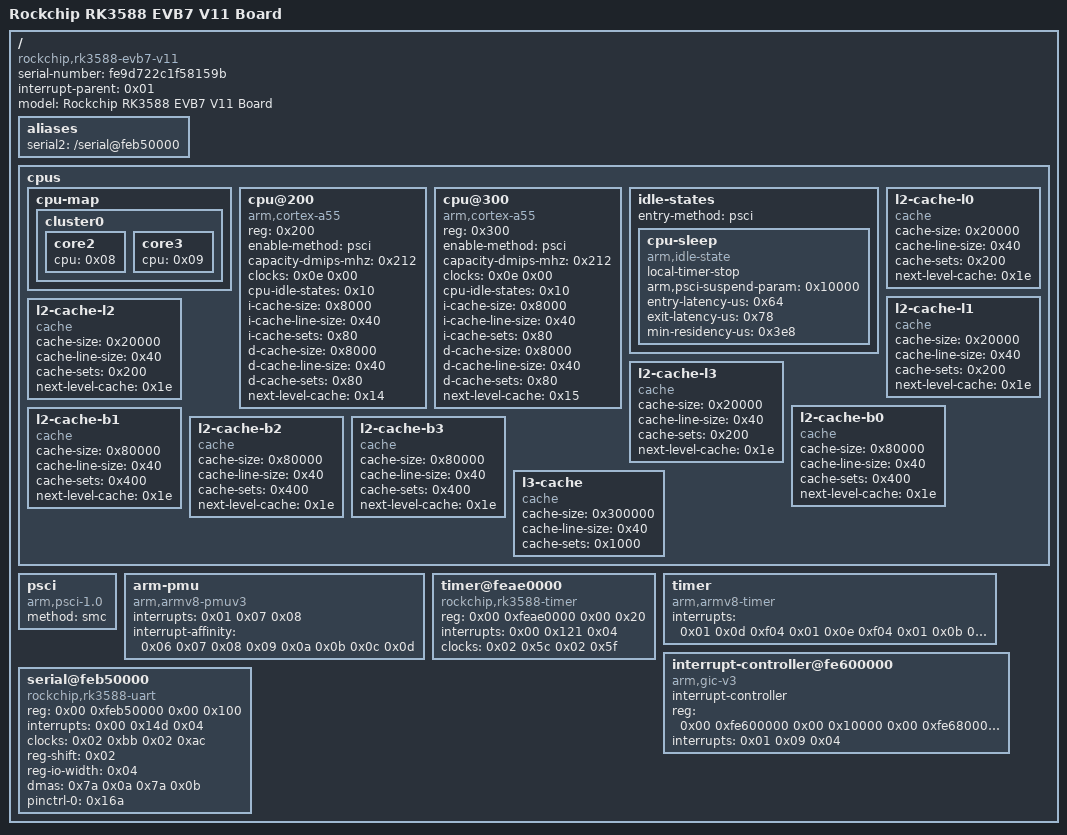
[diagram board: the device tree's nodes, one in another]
/dts-v1/;
/ {
	serial-number = "fe9d722c1f58159b";
	compatible = "rockchip,rk3588-evb7-v11\0rockchip,rk3588";
	interrupt-parent = <0x01>;
	#address-cells = <0x02>;
	#size-cells = <0x02>;
	model = "Rockchip RK3588 EVB7 V11 Board";

	aliases {
		serial2 = "/serial@feb50000";
	};

	cpus {
		#address-cells = <0x01>;
		#size-cells = <0x00>;

		cpu-map {
			cluster0 {
				core2 {
					cpu = <0x08>;
				};
				core3 {
					cpu = <0x09>;
				};
			};
		};

		cpu@200 {
			device_type = "cpu";
			compatible = "arm,cortex-a55";
			reg = <0x200>;
			enable-method = "psci";
			capacity-dmips-mhz = <0x212>;
			clocks = <0x0e 0x00>;
			cpu-idle-states = <0x10>;
			i-cache-size = <0x8000>;
			i-cache-line-size = <0x40>;
			i-cache-sets = <0x80>;
			d-cache-size = <0x8000>;
			d-cache-line-size = <0x40>;
			d-cache-sets = <0x80>;
			next-level-cache = <0x14>;
			phandle = <0x08>;
		};

		cpu@300 {
			device_type = "cpu";
			compatible = "arm,cortex-a55";
			reg = <0x300>;
			enable-method = "psci";
			capacity-dmips-mhz = <0x212>;
			clocks = <0x0e 0x00>;
			cpu-idle-states = <0x10>;
			i-cache-size = <0x8000>;
			i-cache-line-size = <0x40>;
			i-cache-sets = <0x80>;
			d-cache-size = <0x8000>;
			d-cache-line-size = <0x40>;
			d-cache-sets = <0x80>;
			next-level-cache = <0x15>;
			phandle = <0x09>;
		};

		idle-states {
			entry-method = "psci";
			cpu-sleep {
				compatible = "arm,idle-state";
				local-timer-stop;
				arm,psci-suspend-param = <0x10000>;
				entry-latency-us = <0x64>;
				exit-latency-us = <0x78>;
				min-residency-us = <0x3e8>;
				phandle = <0x10>;
			};
		};

		l2-cache-l0 {
			compatible = "cache";
			cache-size = <0x20000>;
			cache-line-size = <0x40>;
			cache-sets = <0x200>;
			next-level-cache = <0x1e>;
			phandle = <0x11>;
		};

		l2-cache-l1 {
			compatible = "cache";
			cache-size = <0x20000>;
			cache-line-size = <0x40>;
			cache-sets = <0x200>;
			next-level-cache = <0x1e>;
			phandle = <0x13>;
		};

		l2-cache-l2 {
			compatible = "cache";
			cache-size = <0x20000>;
			cache-line-size = <0x40>;
			cache-sets = <0x200>;
			next-level-cache = <0x1e>;
			phandle = <0x14>;
		};

		l2-cache-l3 {
			compatible = "cache";
			cache-size = <0x20000>;
			cache-line-size = <0x40>;
			cache-sets = <0x200>;
			next-level-cache = <0x1e>;
			phandle = <0x15>;
		};

		l2-cache-b0 {
			compatible = "cache";
			cache-size = <0x80000>;
			cache-line-size = <0x40>;
			cache-sets = <0x400>;
			next-level-cache = <0x1e>;
			phandle = <0x17>;
		};

		l2-cache-b1 {
			compatible = "cache";
			cache-size = <0x80000>;
			cache-line-size = <0x40>;
			cache-sets = <0x400>;
			next-level-cache = <0x1e>;
			phandle = <0x19>;
		};

		l2-cache-b2 {
			compatible = "cache";
			cache-size = <0x80000>;
			cache-line-size = <0x40>;
			cache-sets = <0x400>;
			next-level-cache = <0x1e>;
			phandle = <0x1b>;
		};

		l2-cache-b3 {
			compatible = "cache";
			cache-size = <0x80000>;
			cache-line-size = <0x40>;
			cache-sets = <0x400>;
			next-level-cache = <0x1e>;
			phandle = <0x1d>;
		};

		l3-cache {
			compatible = "cache";
			cache-size = <0x300000>;
			cache-line-size = <0x40>;
			cache-sets = <0x1000>;
			phandle = <0x1e>;
		};
	};

	psci {
		compatible = "arm,psci-1.0";
		method = "smc";
	};

	arm-pmu {
		compatible = "arm,armv8-pmuv3";
		interrupts = <0x01 0x07 0x08>;
		interrupt-affinity = <0x06 0x07 0x08 0x09 0x0a 0x0b 0x0c 0x0d>;
		phandle = <0x210>;
	};

	timer@feae0000 {
		compatible = "rockchip,rk3588-timer\0rockchip,rk3288-timer";
		reg = <0x00 0xfeae0000 0x00 0x20>;
		interrupts = <0x00 0x121 0x04>;
		clocks = <0x02 0x5c 0x02 0x5f>;
		clock-names = "pclk\0timer";
		phandle = <0x2b1>;
	};

	timer {
		compatible = "arm,armv8-timer";
		interrupts = <0x01 0x0d 0xf04 0x01 0x0e 0xf04 0x01 0x0b 0xf04 0x01 0x0a 0xf04>;
	};

	interrupt-controller@fe600000 {
		compatible = "arm,gic-v3";
		#interrupt-cells = <0x03>;
		#address-cells = <0x02>;
		#size-cells = <0x02>;
		ranges;
		interrupt-controller;
		reg = <0x00 0xfe600000 0x00 0x10000 0x00 0xfe680000 0x00 0x100000>;
		interrupts = <0x01 0x09 0x04>;
		phandle = <0x01>;
	};

	serial@feb50000 {
		compatible = "rockchip,rk3588-uart\0snps,dw-apb-uart";
		reg = <0x00 0xfeb50000 0x00 0x100>;
		interrupts = <0x00 0x14d 0x04>;
		clocks = <0x02 0xbb 0x02 0xac>;
		clock-names = "baudclk\0apb_pclk";
		reg-shift = <0x02>;
		reg-io-width = <0x04>;
		dmas = <0x7a 0x0a 0x7a 0x0b>;
		pinctrl-names = "default";
		pinctrl-0 = <0x16a>;
		status = "okay";
		phandle = <0x2d1>;
	};	

	__symbols__ {
		cpu_l2 = "/cpus/cpu@200";
		cpu_l3 = "/cpus/cpu@300";
		l2_cache_l0 = "/cpus/l2-cache-l0";
		l2_cache_l1 = "/cpus/l2-cache-l1";
		l2_cache_l2 = "/cpus/l2-cache-l2";
		l2_cache_l3 = "/cpus/l2-cache-l3";
		l2_cache_b0 = "/cpus/l2-cache-b0";
		l2_cache_b1 = "/cpus/l2-cache-b1";
		l2_cache_b2 = "/cpus/l2-cache-b2";
		l2_cache_b3 = "/cpus/l2-cache-b3";
		rktimer = "/timer@feae0000";
		uart2 = "/serial@feb50000";
		gic = "/interrupt-controller@fe600000";
	};	
};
